# ATSAMR35J18B register map
Vendor: Microchip Technology; Series: SAMR35; File version: 0
CPU: CM0+ r0p0, selectable endian, no MPU, no FPU, 2 interrupt priority bits
Registers are 32-bit, read-write, reset 0x0 unless marked. A register's access mark holds for its fields unless they carry their own. Offsets are from the block's base; [hi:lo] are bit positions; {n}, {i} and the like mark numbered series; 'fields as' and 'values as' point back to an identical list; <NAME> marks a mode.

## AES — Advanced Encryption Standard
Base 0x42003400; register names take the prefix AES_
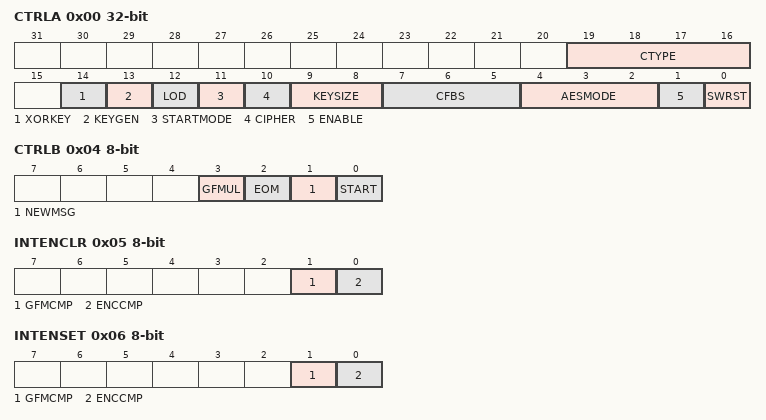
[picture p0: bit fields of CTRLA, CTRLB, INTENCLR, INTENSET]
0x00 CTRLA — Control A
  [19:16] CTYPE — Counter measure types
  [14] XORKEY — Xor Key operation
  [13] KEYGEN — Last key generation
  [12] LOD — LOD Enable
  [11] STARTMODE
  [10] CIPHER — Cipher mode
  [9:8] KEYSIZE
  [7:5] CFBS — CFB Types
  [4:2] AESMODE — AES Modes of operation
  [1] ENABLE
  [0] SWRST — Software Reset
0x04 CTRLB 8-bit — Control B
  [3] GFMUL — GF Multiplication
  [2] EOM — End of message
  [1] NEWMSG — New message
  [0] START — Manual Start
0x05 INTENCLR 8-bit — Interrupt Enable Clear
  [1] GFMCMP — GF Multiplication Complete
  [0] ENCCMP — Encryption Complete
0x06 INTENSET 8-bit — Interrupt Enable Set
  fields as INTENCLR
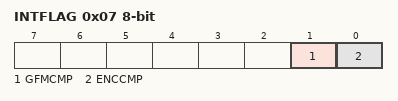
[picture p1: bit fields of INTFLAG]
0x07 INTFLAG 8-bit — Interrupt Flag Status
  fields as INTENCLR
0x08 DATABUFPTR 8-bit — Data buffer pointer
  [1:0] INDATAPTR — Input Data Pointer
0x09 DBGCTRL 8-bit wo — Debug control
  [0] DBGRUN — Debug Run
{0xC+4i} KEYWORD[{i}] (i=0..7) wo — Keyword n
0x38 INDATA
{0x3C+4i} INTVECTV[{i}] (i=0..3) wo — Initialisation Vector n
{0x5C+4i} HASHKEY[{i}] (i=0..3) — Hash key n
{0x6C+4i} GHASH[{i}] (i=0..3) — Galois Hash n
0x80 CIPLEN — Cipher Length
0x84 RANDSEED — Random Seed

## CCL — Configurable Custom Logic
Base 0x43001C00; register names take the prefix CCL_
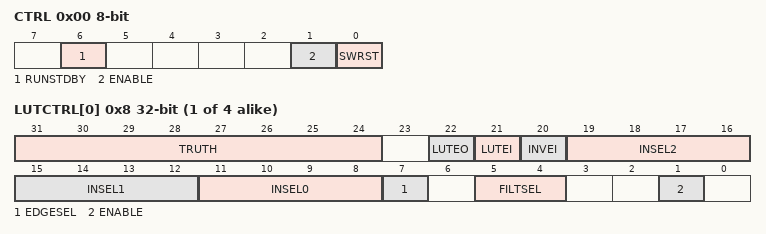
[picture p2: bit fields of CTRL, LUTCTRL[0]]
0x00 CTRL 8-bit — Control
  [6] RUNSTDBY — Run in Standby
    0=DISABLE (Generic clock is not required in standby sleep mode); 1=ENABLE (Generic clock is required in standby sleep mode)
  [1] ENABLE
    0=DISABLE (The peripheral is disabled); 1=ENABLE (The peripheral is enabled)
  [0] SWRST — Software Reset
    0=DISABLE (The peripheral is not reset); 1=ENABLE (The peripheral is reset)
{0x4+i} SEQCTRL[{i}] (i=0..1) 8-bit — SEQ Control x
  [3:0] SEQSEL — Sequential Selection
    0=DISABLE (Sequential logic is disabled); 1=DFF (D flip flop); 2=JK (JK flip flop); 3=LATCH (D latch); 4=RS (RS latch)
{0x8+4i} LUTCTRL[{i}] (i=0..3) — LUT Control x
  [31:24] TRUTH — Truth Value
  [22] LUTEO — LUT Event Output Enable
    0=DISABLE (LUT event output is disabled); 1=ENABLE (LUT event output is enabled)
  [21] LUTEI — LUT Event Input Enable
    0=DISABLE (LUT incoming event is disabled); 1=ENABLE (LUT incoming event is enabled)
  [20] INVEI — Inverted Event Input Enable
    0=DISABLE (Incoming event is not inverted); 1=ENABLE (Incoming event is inverted)
  [19:16] INSEL2 — Input Selection 2
    0=MASK (Masked input); 1=FEEDBACK (Feedback input source); 2=LINK (Linked LUT input source); 3=EVENT (Event input source); 4=IO (I/O pin input source); 5=AC (AC input source); 6=TC (TC input source); 7=ALTTC (Alternate TC input source); 8=TCC (TCC input source); 9=SERCOM (SERCOM input source)
  [15:12] INSEL1 — Input Selection 1
    values as INSEL2
  [11:8] INSEL0 — Input Selection 0
    values as INSEL2
  [7] EDGESEL — Edge Selection
    0=DISABLE (Edge detector is disabled); 1=ENABLE (Edge detector is enabled)
  [5:4] FILTSEL — Filter Selection
    0=DISABLE (Filter disabled); 1=SYNCH (Synchronizer enabled); 2=FILTER (Filter enabled)
  [1] ENABLE — LUT Enable
    0=DISABLE (LUT block is disabled); 1=ENABLE (LUT block is enabled)

## DAC — Digital-to-Analog Converter
Base 0x42003000; register names take the prefix DAC_
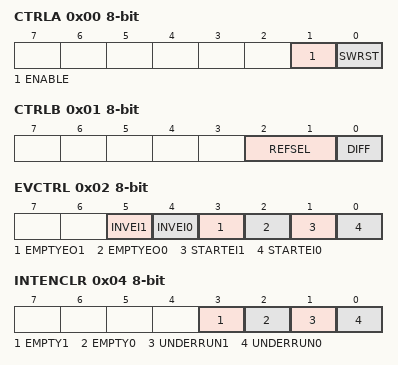
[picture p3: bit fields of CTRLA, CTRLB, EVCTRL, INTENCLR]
0x00 CTRLA 8-bit — Control A
  [1] ENABLE — Enable DAC Controller
  [0] SWRST — Software Reset
0x01 CTRLB 8-bit — Control B
  [2:1] REFSEL — Reference Selection for DAC0/1
    0=VREFPU (External reference unbuffered); 1=VDDANA (Analog supply); 2=VREFPB (External reference buffered); 3=INTREF (Internal bandgap reference)
  [0] DIFF — Differential mode enable
0x02 EVCTRL 8-bit — Event Control
  [5] INVEI1 — Enable Invertion of DAC 1 input event
  [4] INVEI0 — Enable Invertion of DAC 0 input event
  [3] EMPTYEO1 — Data Buffer Empty Event Output DAC 1
  [2] EMPTYEO0 — Data Buffer Empty Event Output DAC 0
  [1] STARTEI1 — Start Conversion Event Input DAC 1
  [0] STARTEI0 — Start Conversion Event Input DAC 0
0x04 INTENCLR 8-bit — Interrupt Enable Clear
  [3] EMPTY1 — Data Buffer 1 Empty Interrupt Enable
  [2] EMPTY0 — Data Buffer 0 Empty Interrupt Enable
  [1] UNDERRUN1 — Underrun Interrupt Enable for DAC 1
  [0] UNDERRUN0 — Underrun Interrupt Enable for DAC 0
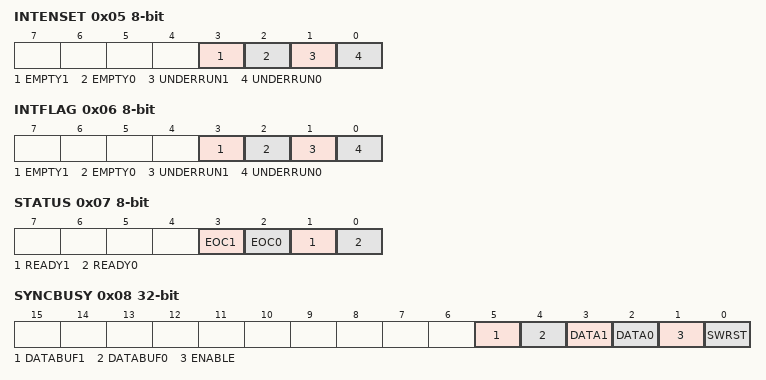
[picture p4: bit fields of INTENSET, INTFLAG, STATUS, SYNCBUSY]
0x05 INTENSET 8-bit — Interrupt Enable Set
  fields as INTENCLR
0x06 INTFLAG 8-bit — Interrupt Flag Status and Clear
  [3] EMPTY1 — Data Buffer 1 Empty
  [2] EMPTY0 — Data Buffer 0 Empty
  [1] UNDERRUN1 — DAC 1 Underrun
  [0] UNDERRUN0 — DAC 0 Underrun
0x07 STATUS 8-bit ro
  [3] EOC1 — DAC 1 End of Conversion
  [2] EOC0 — DAC 0 End of Conversion
  [1] READY1 — DAC 1 Startup Ready
  [0] READY0 — DAC 0 Startup Ready
0x08 SYNCBUSY ro — Synchronization Busy
  [5] DATABUF1 — Data Buffer DAC 1
  [4] DATABUF0 — Data Buffer DAC 0
  [3] DATA1 — Data DAC 1
  [2] DATA0 — Data DAC 0
  [1] ENABLE — DAC Enable Status
  [0] SWRST — Software Reset
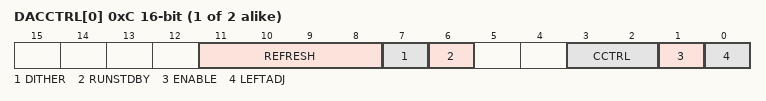
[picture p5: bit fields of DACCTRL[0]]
{0xC+2i} DACCTRL[{i}] (i=0..1) 16-bit — DAC n Control
  [11:8] REFRESH — Refresh period
    0=Do not Refresh; 2=Refresh every 60US; 3=Refresh every 90US; 4=Refresh every 120US; 5=Refresh every 150US; 6=Refresh every 180US; 7=Refresh every 210US; 8=Refresh every 240US; 9=Refresh every 270US; 10=Refresh every 300US; 11=Refresh every 330US; 12=Refresh every 360US; 13=Refresh every 390US; 14=Refresh every 420US; 15=Refresh every 450US
  [7] DITHER — Dithering Mode
  [6] RUNSTDBY — Run in Standby
  [3:2] CCTRL — Current Control
    0=CC100K (GCLK_DAC <= 1.2MHz (100kSPS)); 1=CC1M (1.2MHz < GCLK_DAC <= 6MHz (500kSPS)); 2=CC12M (6MHz < GCLK_DAC <=12MHz (1MSPS))
  [1] ENABLE — Enable DAC0
  [0] LEFTADJ — Left Adjusted Data
{0x10+2i} DATA[{i}] (i=0..1) 16-bit wo — DAC n Data
  [15:0] DATA — DAC0 Data
{0x14+2i} DATABUF[{i}] (i=0..1) 16-bit wo — DAC n Data Buffer
  [15:0] DATABUF — DAC0 Data Buffer
0x18 DBGCTRL 8-bit — Debug Control
  [0] DBGRUN — Debug Run

## Notices in the file
Copyright (c) 2017 Microchip Technology Inc.
SPDX-License-Identifier: Apache-2.0
Licensed under the Apache License, Version 2.0 (the "License");
you may not use this file except in compliance with the License.
You may obtain a copy of the License at
http://www.apache.org/licenses/LICENSE-2.0
Unless required by applicable law or agreed to in writing, software
distributed under the License is distributed on an "AS IS" BASIS,
WITHOUT WARRANTIES OR CONDITIONS OF ANY KIND, either express or implied.
See the License for the specific language governing permissions and
limitations under the License.
